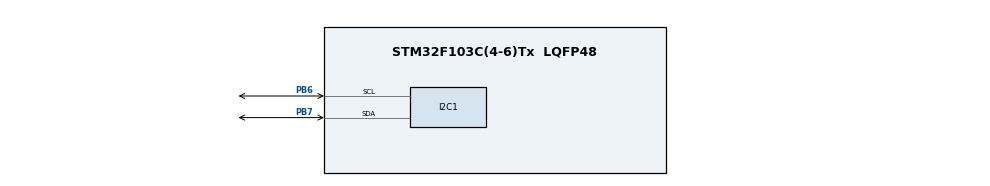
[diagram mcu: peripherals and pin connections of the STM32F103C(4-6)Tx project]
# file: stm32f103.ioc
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Mcu.Family=STM32F1
Mcu.Name=STM32F103C(4-6)Tx
Mcu.Package=LQFP48
NVIC.PriorityGroup=NVIC_PRIORITYGROUP_4
PA13.Mode=Serial_Wire
PA13.Signal=SYS_JTMS-SWDIO
PA14.Mode=Serial_Wire
PA14.Signal=SYS_JTCK-SWCLK
PB6.Mode=I2C
PB6.Signal=I2C1_SCL
PB7.Mode=I2C
PB7.Signal=I2C1_SDA
ProjectManager.HeapSize=0x200
ProjectManager.StackSize=0x400
ProjectManager.TargetToolchain=CMake
RCC.APB1Freq_Value=8000000
RCC.APB2Freq_Value=8000000
board=custom

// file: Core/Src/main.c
/* USER CODE BEGIN Header */
/**
  ******************************************************************************
  * @file           : main.c
  * @brief          : Main program body
  ******************************************************************************
  * @attention
  *
  * Copyright (c) 2026 STMicroelectronics.
  * All rights reserved.
  *
  * This software is licensed under terms that can be found in the LICENSE file
  * in the root directory of this software component.
  * If no LICENSE file comes with this software, it is provided AS-IS.
  *
  ******************************************************************************
  */
/* USER CODE END Header */
#include "main.h"

/* USER CODE BEGIN Includes */
#include "RDA5807M.h"
/* USER CODE END Includes */

I2C_HandleTypeDef hi2c1;

void SystemClock_Config(void);
static void MX_GPIO_Init(void);
static void MX_I2C1_Init(void);
/* USER CODE BEGIN PFP */
rda_status_t rda5807m_i2c_write(uint8_t i2c_addr, uint8_t* data, uint8_t length);
rda_status_t rda5807m_i2c_read(uint8_t i2c_addr, uint8_t reg_addr, uint8_t* buff, uint8_t length);
void global_delay_ms(uint8_t ms);
/* USER CODE END PFP */

int main(void)
{

  /* MCU Configuration--------------------------------------------------------*/

  /* Reset of all peripherals, Initializes the Flash interface and the Systick. */
  HAL_Init();

  /* Configure the system clock */
  SystemClock_Config();

  /* Initialize all configured peripherals */
  MX_GPIO_Init();
  MX_I2C1_Init();
  /* USER CODE BEGIN 2 */

  static rda5807m_t handle;
  handle.i2c_write = rda5807m_i2c_write;
  handle.i2c_read = rda5807m_i2c_read;
  handle.delay_ms = global_delay_ms;

  rda5807m_init(&handle);
  rda5807m_tune_frequency(&handle, 880);

  /* USER CODE END 2 */

  /* Infinite loop */
  while (1)
  {

  }
}

void SystemClock_Config(void)
{
  RCC_OscInitTypeDef RCC_OscInitStruct = {0};
  RCC_ClkInitTypeDef RCC_ClkInitStruct = {0};

  /** Initializes the RCC Oscillators according to the specified parameters
  * in the RCC_OscInitTypeDef structure.
  */
  RCC_OscInitStruct.OscillatorType = RCC_OSCILLATORTYPE_HSI;
  RCC_OscInitStruct.HSIState = RCC_HSI_ON;
  RCC_OscInitStruct.HSICalibrationValue = RCC_HSICALIBRATION_DEFAULT;
  RCC_OscInitStruct.PLL.PLLState = RCC_PLL_NONE;
  if (HAL_RCC_OscConfig(&RCC_OscInitStruct) != HAL_OK)
  {
    Error_Handler();
  }

  /** Initializes the CPU, AHB and APB buses clocks
  */
  RCC_ClkInitStruct.ClockType = RCC_CLOCKTYPE_HCLK|RCC_CLOCKTYPE_SYSCLK
                              |RCC_CLOCKTYPE_PCLK1|RCC_CLOCKTYPE_PCLK2;
  RCC_ClkInitStruct.SYSCLKSource = RCC_SYSCLKSOURCE_HSI;
  RCC_ClkInitStruct.AHBCLKDivider = RCC_SYSCLK_DIV1;
  RCC_ClkInitStruct.APB1CLKDivider = RCC_HCLK_DIV1;
  RCC_ClkInitStruct.APB2CLKDivider = RCC_HCLK_DIV1;

  if (HAL_RCC_ClockConfig(&RCC_ClkInitStruct, FLASH_LATENCY_0) != HAL_OK)
  {
    Error_Handler();
  }
}

static void MX_I2C1_Init(void)
{

  hi2c1.Instance = I2C1;
  hi2c1.Init.ClockSpeed = 100000;
  hi2c1.Init.DutyCycle = I2C_DUTYCYCLE_2;
  hi2c1.Init.OwnAddress1 = 0;
  hi2c1.Init.AddressingMode = I2C_ADDRESSINGMODE_7BIT;
  hi2c1.Init.DualAddressMode = I2C_DUALADDRESS_DISABLE;
  hi2c1.Init.OwnAddress2 = 0;
  hi2c1.Init.GeneralCallMode = I2C_GENERALCALL_DISABLE;
  hi2c1.Init.NoStretchMode = I2C_NOSTRETCH_DISABLE;
  if (HAL_I2C_Init(&hi2c1) != HAL_OK)
  {
    Error_Handler();
  }

}

static void MX_GPIO_Init(void)
{

  /* GPIO Ports Clock Enable */
  __HAL_RCC_GPIOA_CLK_ENABLE();
  __HAL_RCC_GPIOB_CLK_ENABLE();

}

/* USER CODE BEGIN 4 */
rda_status_t rda5807m_i2c_write(uint8_t i2c_addr, uint8_t* data, uint8_t length) {
  HAL_StatusTypeDef result = HAL_I2C_Master_Transmit(
      &hi2c1,
      (i2c_addr << 1),
      data,
      length,
      HAL_MAX_DELAY
  );

  if (result == HAL_OK) {
    return RDA_OK;
  } else {
    return RDA_I2C_ERROR;
  }
}

rda_status_t rda5807m_i2c_read(uint8_t i2c_addr, uint8_t reg_addr, uint8_t* buff, uint8_t length) {
  HAL_StatusTypeDef result = HAL_I2C_Mem_Read(
    &hi2c1,
    (i2c_addr << 1),
    reg_addr,
    1,
    buff,
    length,
    HAL_MAX_DELAY
  );

  if (result == HAL_OK) {
    return RDA_OK;
  } else {
    return RDA_I2C_ERROR;
  }
}

void global_delay_ms(uint8_t ms) {
  HAL_Delay(ms);
}
/* USER CODE END 4 */

void Error_Handler(void)
{
  __disable_irq();
  while (1)
  {
  }
}
